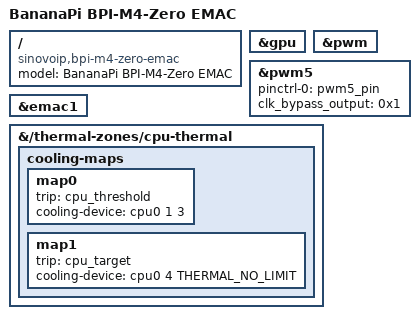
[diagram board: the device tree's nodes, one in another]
// SPDX-License-Identifier: (GPL-2.0+ OR MIT)
// Copyright (c) 2026 BPI-SINOVOIP

/dts-v1/;

#include "sun50i-h618-bananapi-m4-zero.dts"

/ {
	model = "BananaPi BPI-M4-Zero EMAC";
	compatible = "sinovoip,bpi-m4-zero-emac", "sinovoip,bpi-m4-zero",
		     "allwinner,sun50i-h618";
};

&gpu {
	status = "okay";
};

&pwm {
	status = "okay";
};

&pwm5 {
	pinctrl-names = "default";
	pinctrl-0 = <&pwm5_pin>;
	clk_bypass_output = <0x1>;
	status = "okay";
};

&emac1 {
	status = "okay";
};

&{/thermal-zones/cpu-thermal} {
	cooling-maps {
		map0 {
			trip = <&cpu_threshold>;
			cooling-device = <&cpu0 1 3>;
		};

		map1 {
			trip = <&cpu_target>;
			cooling-device = <&cpu0 4 THERMAL_NO_LIMIT>;
		};
	};
};
